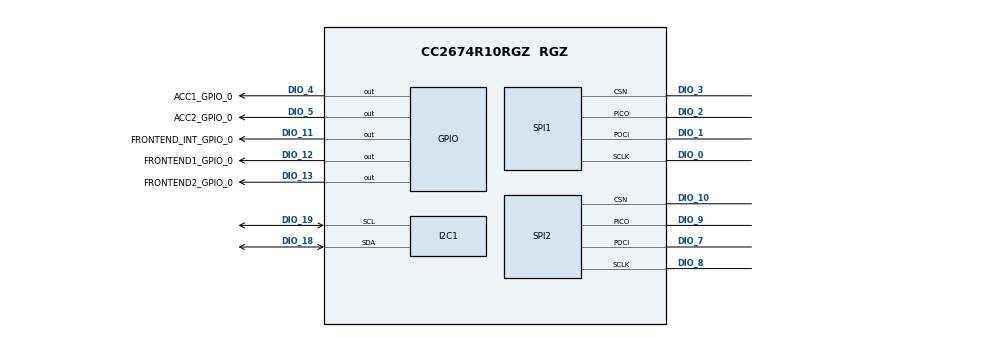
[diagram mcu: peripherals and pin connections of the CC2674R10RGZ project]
/**
 * @cliArgs --device "CC2674R10RGZ" --part "Default" --package "RGZ" --rtos "tirtos7" --product "simplelink_cc13xx_cc26xx_sdk@8.32.00.07"
 * @versions {"tool":"1.27.0+4565"}
 */

/**
 * Import the modules used in this configuration.
 */
const ble      = scripting.addModule("/ti/ble5stack/ble");
const rfdesign = scripting.addModule("/ti/devices/radioconfig/rfdesign");
const GPIO     = scripting.addModule("/ti/drivers/GPIO", {}, false);
const GPIO11   = GPIO.addInstance();
const GPIO12   = GPIO.addInstance();
const GPIO13   = GPIO.addInstance();
const GPIO14   = GPIO.addInstance();
const GPIO15   = GPIO.addInstance();
const I2C      = scripting.addModule("/ti/drivers/I2C", {}, false);
const I2C1     = I2C.addInstance();
const SPI      = scripting.addModule("/ti/drivers/SPI", {}, false);
const SPI1     = SPI.addInstance();
const SPI2     = SPI.addInstance();

/**
 * Write custom configuration values to the imported modules.
 */
ble.radioConfig.codeExportConfig.$name = "ti_devices_radioconfig_code_export_param0";
ble.connUpdateParamsPeripheral.$name   = "ti_ble5stack_general_ble_conn_update_params0";
ble.advSet1.$name                      = "ti_ble5stack_broadcaster_advertisement_set0";
ble.advSet1.advParam1.$name            = "ti_ble5stack_broadcaster_advertisement_params0";
ble.advSet1.advData1.$name             = "ti_ble5stack_broadcaster_advertisement_data0";
ble.advSet1.scanRes1.$name             = "ti_ble5stack_broadcaster_advertisement_data1";
ble.advSet2.$name                      = "ti_ble5stack_broadcaster_advertisement_set1";
ble.advSet2.advParam2.$name            = "ti_ble5stack_broadcaster_advertisement_params1";
ble.advSet2.advData2.$name             = "ti_ble5stack_broadcaster_advertisement_data2";
ble.advSet2.scanRes2.$name             = "ti_ble5stack_broadcaster_advertisement_data3";

rfdesign.fe24g = "IS_RFP";

GPIO11.$name           = "ACC1_GPIO_0";
GPIO11.gpioPin.$assign = "DIO_4";

GPIO12.$name           = "ACC2_GPIO_0";
GPIO12.gpioPin.$assign = "DIO_5";

GPIO13.$name           = "FRONTEND_INT_GPIO_0";
GPIO13.gpioPin.$assign = "DIO_11";

GPIO14.$name           = "FRONTEND1_GPIO_0";
GPIO14.gpioPin.$assign = "DIO_12";

GPIO15.$name           = "FRONTEND2_GPIO_0";
GPIO15.gpioPin.$assign = "DIO_13";

I2C1.$name              = "BMS_I2C_0";
I2C1.i2c.sdaPin.$assign = "DIO_18";
I2C1.i2c.sclPin.$assign = "DIO_19";

const CCFG              = scripting.addModule("/ti/devices/CCFG", {}, false);
CCFG.ccfgTemplate.$name = "ti_devices_CCFG_CCFGCC26XXTemplate0";

SPI1.$name               = "ACC_SPI_0";
SPI1.mode                = "Four Pin CS Active High";
SPI1.spi.sclkPin.$assign = "DIO_0";
SPI1.spi.pociPin.$assign = "DIO_1";
SPI1.spi.picoPin.$assign = "DIO_2";
SPI1.spi.csnPin.$assign  = "DIO_3";

SPI2.$name               = "FRONTEND_SPI_0";
SPI2.mode                = "Four Pin CS Active Low";
SPI2.spi.sclkPin.$assign = "DIO_8";
SPI2.spi.pociPin.$assign = "DIO_7";
SPI2.spi.picoPin.$assign = "DIO_9";
SPI2.spi.csnPin.$assign  = "DIO_10";

/**
 * Pinmux solution for unlocked pins/peripherals. This ensures that minor changes to the automatic solver in a future
 * version of the tool will not impact the pinmux you originally saw.  These lines can be completely deleted in order to
 * re-solve from scratch.
 */
I2C1.i2c.$suggestSolution              = "I2C0";
SPI1.spi.$suggestSolution              = "SPI3";
SPI1.spi.dmaRxChannel.$suggestSolution = "DMA_CH25";
SPI1.spi.dmaTxChannel.$suggestSolution = "DMA_CH26";
SPI2.spi.$suggestSolution              = "SPI2";
SPI2.spi.dmaRxChannel.$suggestSolution = "DMA_CH19";
SPI2.spi.dmaTxChannel.$suggestSolution = "DMA_CH20";
